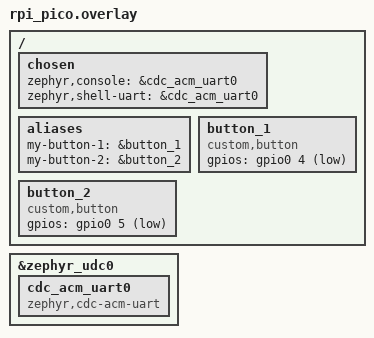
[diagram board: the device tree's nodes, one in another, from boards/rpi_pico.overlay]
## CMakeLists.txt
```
cmake_minimum_required(VERSION 3.20)

set(EXTRA_ZEPHYR_MODULES "${CMAKE_CURRENT_SOURCE_DIR}/../../modules/rp2040_bootloader" "${CMAKE_CURRENT_SOURCE_DIR}/../../modules/button")

# set(DTC_OVERLAY_FILE "${CMAKE_CURRENT_SOURCE_DIR}/app.overlay")
# set(DTS_ROOT "${CMAKE_CURRENT_SOURCE_DIR}")

find_package(Zephyr REQUIRED HINTS $ENV{ZEPHYR_BASE})
project(my_cpp23_project)

# Use absolute pathing based on where this CMakeLists.txt lives
target_sources(app PRIVATE ${CMAKE_CURRENT_LIST_DIR}/src/main.cpp)

target_compile_features(app PUBLIC cxx_std_23)
```

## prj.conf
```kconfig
# Enable C++ Support
CONFIG_CPP=y
CONFIG_STD_CPP23=y
CONFIG_EXTERNAL_LIBCPP=y

# Use Newlib
CONFIG_NEWLIB_LIBC=y

# Generic Zephyr settings
CONFIG_GPIO=y
CONFIG_SPI=y

# Monitoring and stuff
CONFIG_USB_DEVICE_STACK_NEXT=y
CONFIG_USBD_CDC_ACM_CLASS=y
CONFIG_CDC_ACM_SERIAL_INITIALIZE_AT_BOOT=y
CONFIG_SERIAL=y
CONFIG_CONSOLE=y
CONFIG_UART_CONSOLE=y
CONFIG_UART_LINE_CTRL=y

# Playground
CONFIG_SHELL=y
CONFIG_DEVICE_SHELL=y
CONFIG_UART_INTERRUPT_DRIVEN=y

# RP2040 Bootloader module
CONFIG_RP2040_BOOTLOADER=y

# Custom Button Driver
CONFIG_CUSTOM_BUTTON=y
CONFIG_LOG_DEFAULT_LEVEL=4
```

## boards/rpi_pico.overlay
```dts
/ {
    chosen {
        zephyr,console = &cdc_acm_uart0;
        zephyr,shell-uart = &cdc_acm_uart0;
    };

    aliases {
        my-button-1 = &button_1;
        my-button-2 = &button_2;
    };

    button_1: button_1 {
        compatible = "custom,button";
        gpios = <&gpio0 4 (GPIO_ACTIVE_LOW | GPIO_PULL_UP)>;
    };

    button_2: button_2 {
        compatible = "custom,button";
        gpios = <&gpio0 5 (GPIO_ACTIVE_LOW | GPIO_PULL_UP)>;
    };
};

&zephyr_udc0 {
    cdc_acm_uart0: cdc_acm_uart0 {
        compatible = "zephyr,cdc-acm-uart";
    };
};
```

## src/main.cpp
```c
#include <zephyr/drivers/gpio.h>
#include <zephyr/kernel.h>
#include "zephyr/device.h"
#include "button.h"
#include "bootloader_cmd.h"
#include "zephyr/sys/printk.h"

// Constants
static const int32_t sleep_time_ms = 100;

static const struct device *btn_1 = DEVICE_DT_GET(DT_ALIAS(my_button_1));
static const struct device *btn_2 = DEVICE_DT_GET(DT_ALIAS(my_button_2));

int main(void)
{
    printk("Starting...\r\n");

    int ret;
    uint8_t state1;
    uint8_t state2;

    if (!(device_is_ready(btn_1) && device_is_ready(btn_2))) {
        printk("Error: buttons are not ready!\r\n");
        return -1;
    }

    const struct button_api *btn_api = (const struct button_api *)btn_1->api; // Just a pointer to a function

    while (1) {
        ret = btn_api->get(btn_1, &state1);
        if (ret < 0) {
            printk("Error (%d): failed to read button 1 pin\r\n", ret);
            continue;
        }

        ret = btn_api->get(btn_2, &state2);
        if (ret < 0) {
            printk("Error (%d): failed to read button 1 pin\r\n", ret);
            continue;
        }

        printk("%d %d \r\n", state1, state2);

        k_sleep(K_MSEC(sleep_time_ms));
    }

    (void)cmd_bootloader; // Prevent LSP error
    return 0;
}
```
